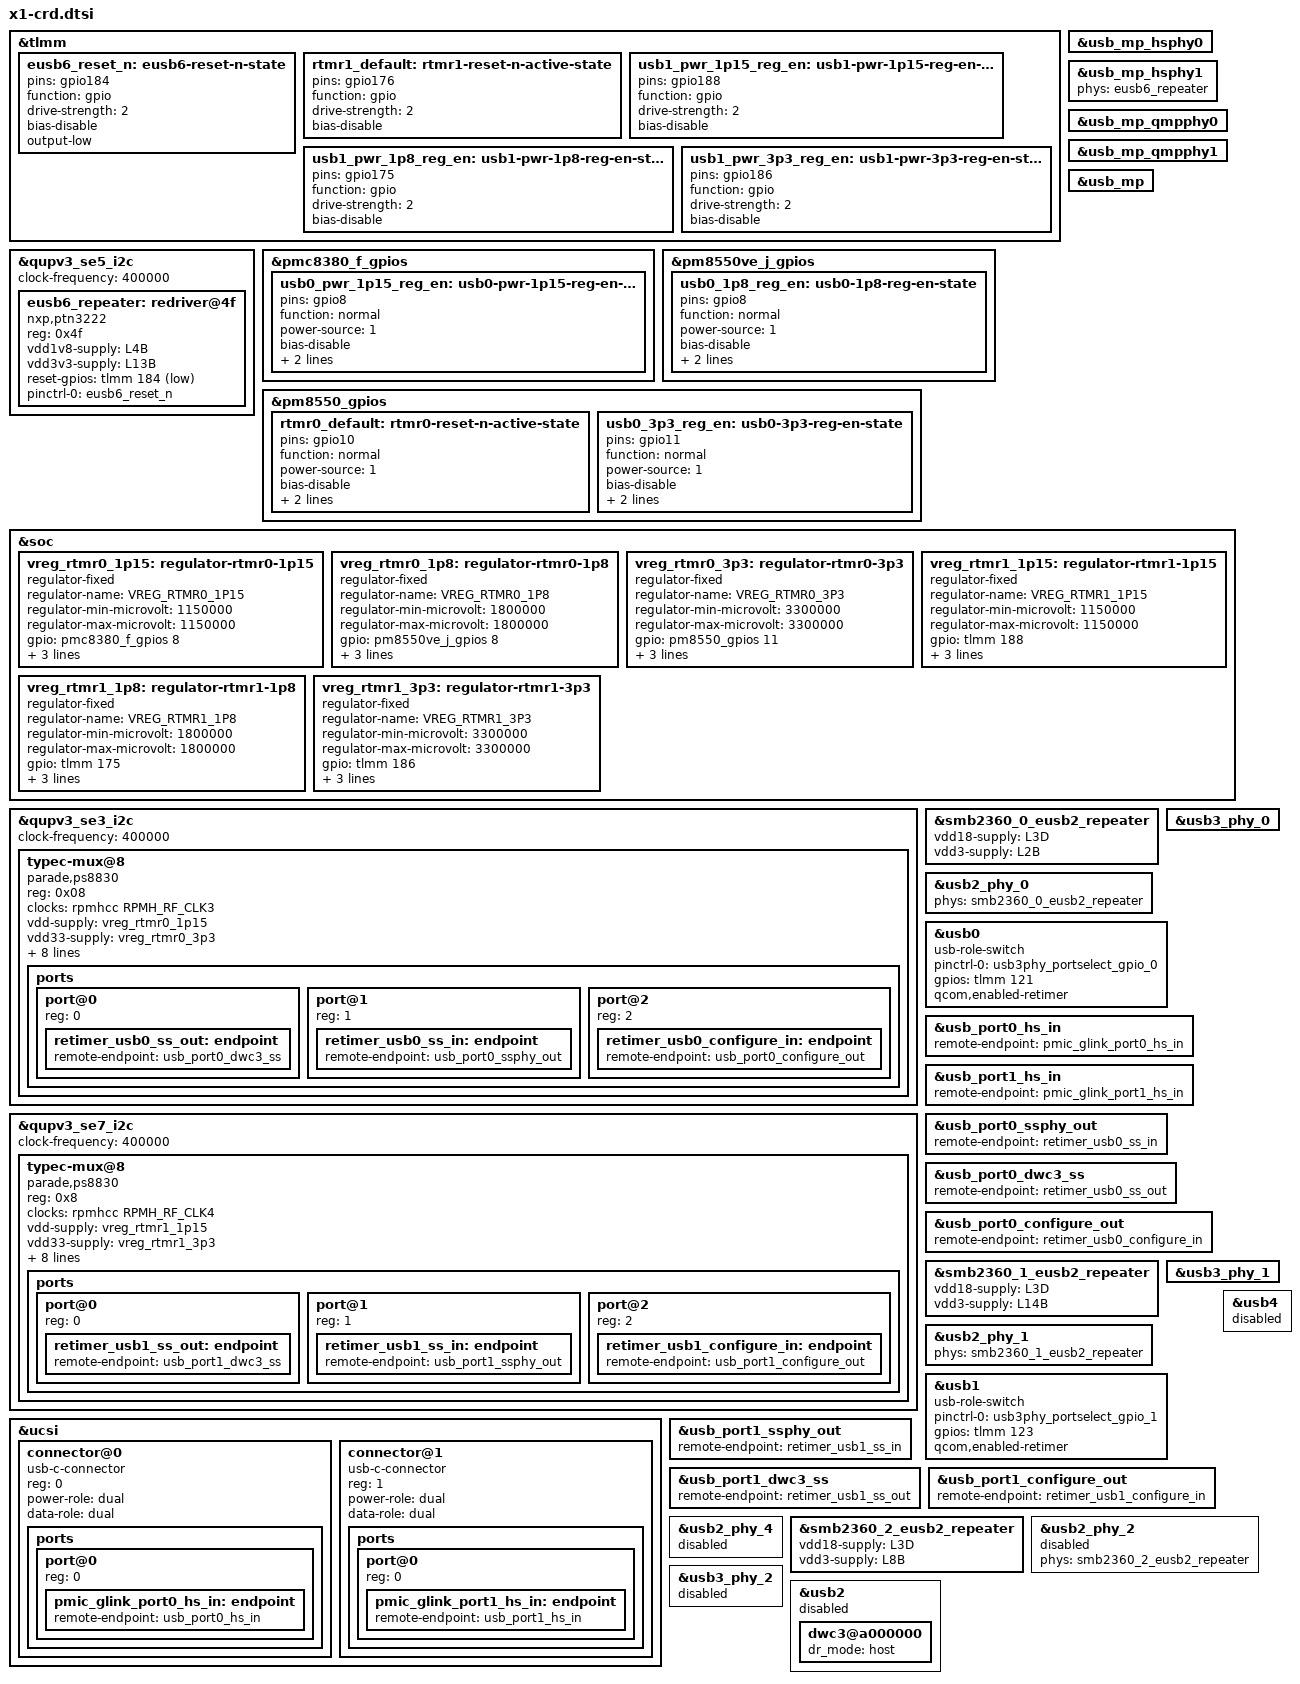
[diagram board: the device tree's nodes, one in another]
// SPDX-License-Identifier: BSD-3-Clause
/*
 * Copyright (c) Qualcomm Technologies, Inc. and/or its subsidiaries.
 */

#include <dt-bindings/gpio/gpio.h>
#include <dt-bindings/clock/qcom,rpmh.h>

&tlmm {
	eusb6_reset_n: eusb6-reset-n-state {
		pins = "gpio184";
		function = "gpio";
		drive-strength = <2>;
		bias-disable;
		output-low;
	};
};

&qupv3_se5_i2c {
	clock-frequency = <400000>;

	status = "okay";

	eusb6_repeater: redriver@4f {
		compatible = "nxp,ptn3222";
		reg = <0x4f>;

		vdd1v8-supply = <&L4B>;
		vdd3v3-supply = <&L13B>;

		reset-gpios = <&tlmm 184 GPIO_ACTIVE_LOW>;

		pinctrl-0 = <&eusb6_reset_n>;
		pinctrl-names = "default";

		#phy-cells = <0>;
	};
};

&usb_mp_hsphy0 {
	status = "okay";
};

&usb_mp_hsphy1 {
	phys = <&eusb6_repeater>;
	status = "okay";
};

&usb_mp_qmpphy0 {
	status = "okay";
};

&usb_mp_qmpphy1 {
	status = "okay";
};

&usb_mp {
	status = "okay";
};

&pmc8380_f_gpios {
	usb0_pwr_1p15_reg_en: usb0-pwr-1p15-reg-en-state {
		pins = "gpio8";
		function = "normal";
		power-source = <1>; /* 1.8V */
		bias-disable;
		input-disable;
		output-enable;
	};
};

&pm8550ve_j_gpios {
	usb0_1p8_reg_en: usb0-1p8-reg-en-state {
		pins = "gpio8";
		function = "normal";
		power-source = <1>; /* 1.8V */
		bias-disable;
		input-disable;
		output-enable;
	};
};

&pm8550_gpios {
	rtmr0_default: rtmr0-reset-n-active-state {
		pins = "gpio10";
		function = "normal";
		power-source = <1>; /* 1.8V */
		bias-disable;
		input-disable;
		output-enable;
	};

	usb0_3p3_reg_en: usb0-3p3-reg-en-state {
		pins = "gpio11";
		function = "normal";
		power-source = <1>; /* 3.3V */
		bias-disable;
		input-disable;
		output-enable;
	};
};

&soc {
	vreg_rtmr0_1p15: regulator-rtmr0-1p15 {
		compatible = "regulator-fixed";

		regulator-name = "VREG_RTMR0_1P15";
		regulator-min-microvolt = <1150000>;
		regulator-max-microvolt = <1150000>;

		gpio = <&pmc8380_f_gpios 8 GPIO_ACTIVE_HIGH>;
		enable-active-high;
		pinctrl-0 = <&usb0_pwr_1p15_reg_en>;
		pinctrl-names = "default";

		regulator-boot-on;
	};

	vreg_rtmr0_1p8: regulator-rtmr0-1p8 {
		compatible = "regulator-fixed";

		regulator-name = "VREG_RTMR0_1P8";
		regulator-min-microvolt = <1800000>;
		regulator-max-microvolt = <1800000>;

		gpio = <&pm8550ve_j_gpios 8 GPIO_ACTIVE_HIGH>;
		enable-active-high;

		pinctrl-0 = <&usb0_1p8_reg_en>;
		pinctrl-names = "default";

		regulator-boot-on;
	};

	vreg_rtmr0_3p3: regulator-rtmr0-3p3 {
		compatible = "regulator-fixed";

		regulator-name = "VREG_RTMR0_3P3";
		regulator-min-microvolt = <3300000>;
		regulator-max-microvolt = <3300000>;

		gpio = <&pm8550_gpios 11 GPIO_ACTIVE_HIGH>;
		enable-active-high;

		pinctrl-0 = <&usb0_3p3_reg_en>;
		pinctrl-names = "default";

		regulator-boot-on;
	};

	vreg_rtmr1_1p15: regulator-rtmr1-1p15 {
		compatible = "regulator-fixed";

		regulator-name = "VREG_RTMR1_1P15";
		regulator-min-microvolt = <1150000>;
		regulator-max-microvolt = <1150000>;

		gpio = <&tlmm 188 GPIO_ACTIVE_HIGH>;
		enable-active-high;

		pinctrl-0 = <&usb1_pwr_1p15_reg_en>;
		pinctrl-names = "default";

		regulator-boot-on;
	};

	vreg_rtmr1_1p8: regulator-rtmr1-1p8 {
		compatible = "regulator-fixed";

		regulator-name = "VREG_RTMR1_1P8";
		regulator-min-microvolt = <1800000>;
		regulator-max-microvolt = <1800000>;

		gpio = <&tlmm 175 GPIO_ACTIVE_HIGH>;
		enable-active-high;

		pinctrl-0 = <&usb1_pwr_1p8_reg_en>;
		pinctrl-names = "default";

		regulator-boot-on;
	};

	vreg_rtmr1_3p3: regulator-rtmr1-3p3 {
		compatible = "regulator-fixed";

		regulator-name = "VREG_RTMR1_3P3";
		regulator-min-microvolt = <3300000>;
		regulator-max-microvolt = <3300000>;

		gpio = <&tlmm 186 GPIO_ACTIVE_HIGH>;
		enable-active-high;

		pinctrl-0 = <&usb1_pwr_3p3_reg_en>;
		pinctrl-names = "default";

		regulator-boot-on;
	};
};

&tlmm {
	rtmr1_default: rtmr1-reset-n-active-state {
		pins = "gpio176";
		function = "gpio";
		drive-strength = <2>;
		bias-disable;
	};

	usb1_pwr_1p15_reg_en: usb1-pwr-1p15-reg-en-state {
		pins = "gpio188";
		function = "gpio";
		drive-strength = <2>;
		bias-disable;
	};

	usb1_pwr_1p8_reg_en: usb1-pwr-1p8-reg-en-state {
		pins = "gpio175";
		function = "gpio";
		drive-strength = <2>;
		bias-disable;
	};

	usb1_pwr_3p3_reg_en: usb1-pwr-3p3-reg-en-state {
		pins = "gpio186";
		function = "gpio";
		drive-strength = <2>;
		bias-disable;
	};
};

&qupv3_se3_i2c {
	clock-frequency = <400000>;

	status = "okay";

	typec-mux@8 {
		compatible = "parade,ps8830";
		reg = <0x08>;

		clocks = <&rpmhcc RPMH_RF_CLK3>;

		vdd-supply = <&vreg_rtmr0_1p15>;
		vdd33-supply = <&vreg_rtmr0_3p3>;
		vdd33-cap-supply = <&vreg_rtmr0_3p3>;
		vddar-supply = <&vreg_rtmr0_1p15>;
		vddat-supply = <&vreg_rtmr0_1p15>;
		vddio-supply = <&vreg_rtmr0_1p8>;

		reset-gpios = <&pm8550_gpios 10 GPIO_ACTIVE_LOW>;
		pinctrl-0 = <&rtmr0_default>;
		pinctrl-names = "default";

		retimer-switch;
		orientation-switch;

		ports {
			#address-cells = <1>;
			#size-cells = <0>;

			port@0 {
				reg = <0>;

				retimer_usb0_ss_out: endpoint {
					remote-endpoint = <&usb_port0_dwc3_ss>;
				};
			};

			port@1 {
				reg = <1>;

				retimer_usb0_ss_in: endpoint {
					remote-endpoint = <&usb_port0_ssphy_out>;
				};
			};

			port@2 {
				reg = <2>;

				retimer_usb0_configure_in: endpoint {
					remote-endpoint = <&usb_port0_configure_out>;
				};
			};
		};
	};
};

&qupv3_se7_i2c {
	clock-frequency = <400000>;

	status = "okay";

	typec-mux@8 {
		compatible = "parade,ps8830";
		reg = <0x8>;

		clocks = <&rpmhcc RPMH_RF_CLK4>;

		vdd-supply = <&vreg_rtmr1_1p15>;
		vdd33-supply = <&vreg_rtmr1_3p3>;
		vdd33-cap-supply = <&vreg_rtmr1_3p3>;
		vddar-supply = <&vreg_rtmr1_1p15>;
		vddat-supply = <&vreg_rtmr1_1p15>;
		vddio-supply = <&vreg_rtmr1_1p8>;

		reset-gpios = <&tlmm 176 GPIO_ACTIVE_LOW>;

		pinctrl-0 = <&rtmr1_default>;
		pinctrl-names = "default";

		retimer-switch;
		orientation-switch;

		ports {
			#address-cells = <1>;
			#size-cells = <0>;

			port@0 {
				reg = <0>;

				retimer_usb1_ss_out: endpoint {
					remote-endpoint = <&usb_port1_dwc3_ss>;
				};
			};

			port@1 {
				reg = <1>;

				retimer_usb1_ss_in: endpoint {
					remote-endpoint = <&usb_port1_ssphy_out>;
				};
			};

			port@2 {
				reg = <2>;

				retimer_usb1_configure_in: endpoint {
					remote-endpoint = <&usb_port1_configure_out>;
				};
			};
		};
	};
};

&smb2360_0_eusb2_repeater {
	vdd18-supply = <&L3D>;
	vdd3-supply = <&L2B>;
};

&usb2_phy_0 {
	phys = <&smb2360_0_eusb2_repeater>;
	status = "okay";
};

&usb3_phy_0 {
	status = "okay";
};

&usb0 {
	status = "okay";
	usb-role-switch;
	pinctrl-names = "default";
	pinctrl-0 = <&usb3phy_portselect_gpio_0>;
	gpios = <&tlmm 121 0>;
	qcom,enabled-retimer;
};

&ucsi {
	/* Left-side front port */
	connector@0 {
		compatible = "usb-c-connector";
		reg = <0>;
		power-role = "dual";
		data-role = "dual";

		ports {
			#address-cells = <1>;
			#size-cells = <0>;

			port@0 {
				reg = <0>;

				pmic_glink_port0_hs_in: endpoint {
					remote-endpoint = <&usb_port0_hs_in>;
				};
			};
		};
	};

	/* Left-side front port */
	connector@1 {
		compatible = "usb-c-connector";
		reg = <1>;
		power-role = "dual";
		data-role = "dual";

		ports {
			#address-cells = <1>;
			#size-cells = <0>;

			port@0 {
				reg = <0>;

				pmic_glink_port1_hs_in: endpoint {
					remote-endpoint = <&usb_port1_hs_in>;
				};
			};
		};
	};
};

&usb_port0_hs_in {
	remote-endpoint = <&pmic_glink_port0_hs_in>;
};

&usb_port1_hs_in {
	remote-endpoint = <&pmic_glink_port1_hs_in>;
};

&usb_port0_ssphy_out {
	remote-endpoint = <&retimer_usb0_ss_in>;
};

&usb_port0_dwc3_ss {
	remote-endpoint = <&retimer_usb0_ss_out>;
};

&usb_port0_configure_out {
	remote-endpoint = <&retimer_usb0_configure_in>;
};

&smb2360_1_eusb2_repeater {
	vdd18-supply = <&L3D>;
	vdd3-supply = <&L14B>;
};

&usb2_phy_1 {
	phys = <&smb2360_1_eusb2_repeater>;
	status = "okay";
};

&usb3_phy_1 {
	status = "okay";
};

&usb1 {
	status = "okay";
	usb-role-switch;
	pinctrl-names = "default";
	pinctrl-0 = <&usb3phy_portselect_gpio_1>;
	gpios = <&tlmm 123 0>;
	qcom,enabled-retimer;
};

&usb_port1_ssphy_out {
	remote-endpoint = <&retimer_usb1_ss_in>;
};

&usb_port1_dwc3_ss {
	remote-endpoint = <&retimer_usb1_ss_out>;
};

&usb_port1_configure_out {
	remote-endpoint = <&retimer_usb1_configure_in>;
};

&usb2_phy_4 {
	status = "disabled";
};

&usb4 {
	status = "disabled";
};

&smb2360_2_eusb2_repeater {
	vdd18-supply = <&L3D>;
	vdd3-supply = <&L8B>;
};

&usb2_phy_2 {
	phys = <&smb2360_2_eusb2_repeater>;
	status = "disabled";
};

&usb3_phy_2 {
	status = "disabled";
};

&usb2 {
	status = "disabled";
	dwc3@a000000 {
		dr_mode = "host";
	};
};
